# trimsir_me14 register map
Registers are access not given, no defined reset value unless marked. A register's access mark holds for its fields unless they carry their own. Offsets are from the block's base; lines under a group give offsets from that group; [hi:lo] are bit positions; {n}, {i} and the like mark numbered series; 'fields as' and 'values as' point back to an identical list; <NAME> marks a mode.

## Memory map
0x40005400 TRIMSIR size 0x400 — Trim System Initilazation Registers

## TRIMSIR — Trim System Initilazation Registers
Base 0x40005400
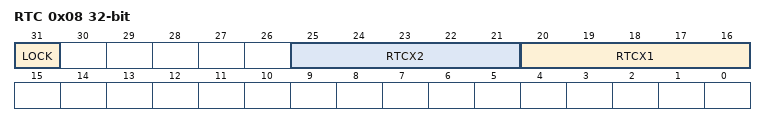
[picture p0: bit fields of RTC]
0x08 RTC — System Init. Configuration Register 2.
  [31] LOCK
  [25:21] RTCX2 — RTC X2 Trim.
  [20:16] RTCX1 — RTC X1 Trim.
0x34 SIR13 — System Init. Configuration Register 13.
  [1:0] SIMOCLKDIV — SIMO Clock Divide while in LP mode.
0x44 SIR17 — System Init. Configuration Register 17.
  [7:6] BUCKCLKSELLP — BUCK Clock Select Low Power Mode.
